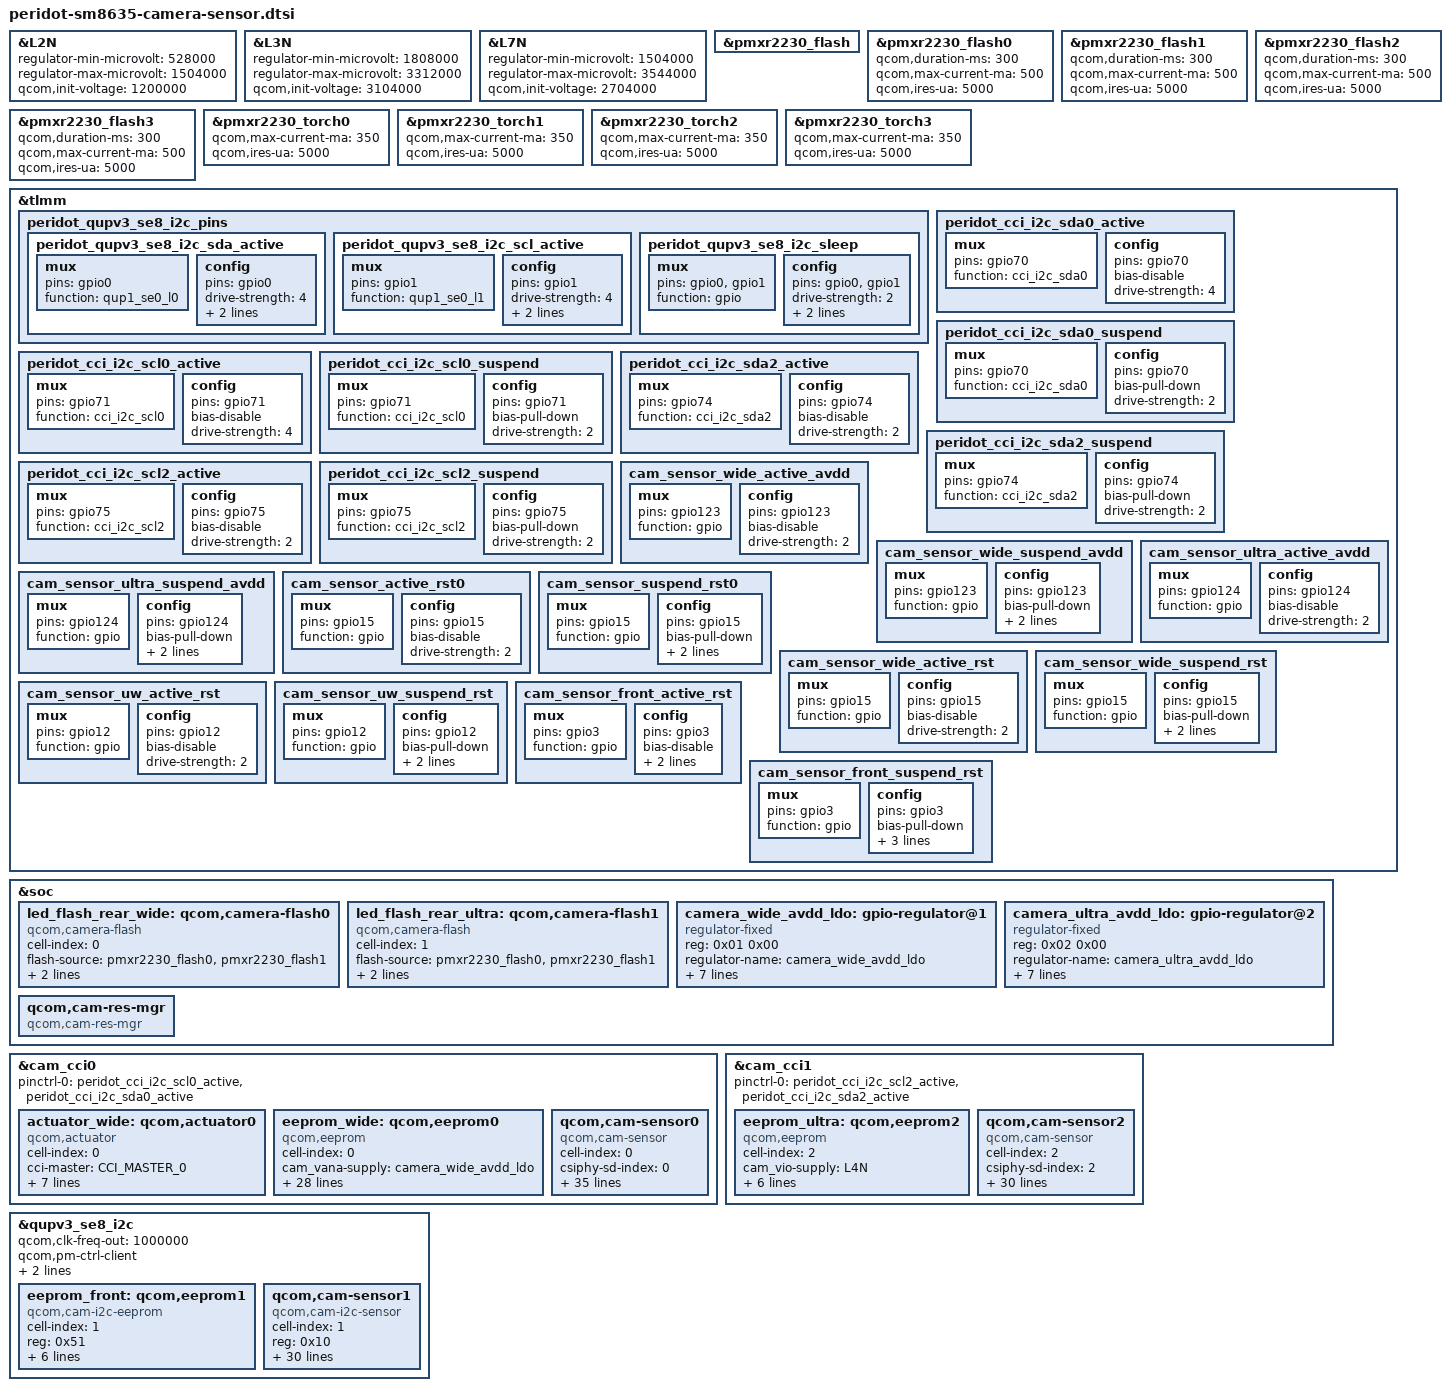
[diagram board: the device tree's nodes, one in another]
#include <dt-bindings/msm-camera.h>

&L2N {
	regulator-min-microvolt = <528000>;
	regulator-max-microvolt = <1504000>;
	qcom,init-voltage = <1200000>;
};

&L3N {
	regulator-min-microvolt = <1808000>;
	regulator-max-microvolt = <3312000>;
	qcom,init-voltage = <3104000>;
};

&L7N {
	regulator-min-microvolt = <1504000>;
	regulator-max-microvolt = <3544000>;
	qcom,init-voltage = <2704000>;
};

&pmxr2230_flash {
	status = "ok";
};

&pmxr2230_flash0 {
	qcom,duration-ms = <300>;
	qcom,max-current-ma = <500>;
	qcom,ires-ua = <5000>;
};

&pmxr2230_flash1 {
	qcom,duration-ms = <300>;
	qcom,max-current-ma = <500>;
	qcom,ires-ua = <5000>;
};

&pmxr2230_flash2 {
	qcom,duration-ms = <300>;
	qcom,max-current-ma = <500>;
	qcom,ires-ua = <5000>;
};

&pmxr2230_flash3 {
	qcom,duration-ms = <300>;
	qcom,max-current-ma = <500>;
	qcom,ires-ua = <5000>;
};

&pmxr2230_torch0{
	qcom,max-current-ma = <350>;
	qcom,ires-ua = <5000>;
};

&pmxr2230_torch1{
	qcom,max-current-ma = <350>;
	qcom,ires-ua = <5000>;
};

&pmxr2230_torch2{
	qcom,max-current-ma = <350>;
	qcom,ires-ua = <5000>;
};

&pmxr2230_torch3{
	qcom,max-current-ma = <350>;
	qcom,ires-ua = <5000>;
};

&tlmm {
	peridot_qupv3_se8_i2c_pins: peridot_qupv3_se8_i2c_pins {
		peridot_qupv3_se8_i2c_sda_active: peridot_qupv3_se8_i2c_sda_active {
			mux {
				pins = "gpio0";
				function = "qup1_se0_l0";
			};

			config {
				pins = "gpio0";
				drive-strength = <4>;
				bias-disable; /* NO PULL */
				qcom,apps;
			};
		};

		peridot_qupv3_se8_i2c_scl_active: peridot_qupv3_se8_i2c_scl_active {
			mux {
				pins = "gpio1";
				function = "qup1_se0_l1";
			};

			config {
				pins = "gpio1";
				drive-strength = <4>;
				bias-disable; /* NO PULL */
				qcom,apps;
			};
		};

		peridot_qupv3_se8_i2c_sleep: peridot_qupv3_se8_i2c_sleep {
			mux {
				pins = "gpio0", "gpio1";
				function = "gpio";
			};

			config {
				pins = "gpio0", "gpio1";
				drive-strength = <2>;
				bias-disable;
				qcom,remote;
			};
		};
	};

	peridot_cci_i2c_sda0_active: peridot_cci_i2c_sda0_active {
		mux {
			/* CLK, DATA */
			pins = "gpio70";
			function = "cci_i2c_sda0";
		};

		config {
			pins = "gpio70";
			bias-disable; /* NO PULL */
			drive-strength = <4>; /* 4 MA */
		};
	};

	peridot_cci_i2c_sda0_suspend: peridot_cci_i2c_sda0_suspend {
		mux {
			/* CLK, DATA */
			pins = "gpio70";
			function = "cci_i2c_sda0";
		};

		config {
			pins = "gpio70";
			bias-pull-down; /* PULL DOWN */
			drive-strength = <2>; /* 2 MA */
		};
	};

	peridot_cci_i2c_scl0_active: peridot_cci_i2c_scl0_active {
		mux {
			/* CLK, DATA */
			pins = "gpio71";
			function = "cci_i2c_scl0";
		};

		config {
			pins = "gpio71";
			bias-disable; /* NO PULL */
			drive-strength = <4>; /* 4 MA */
		};
	};

	peridot_cci_i2c_scl0_suspend: peridot_cci_i2c_scl0_suspend {
		mux {
			/* CLK, DATA */
			pins = "gpio71";
			function = "cci_i2c_scl0";
		};

		config {
			pins = "gpio71";
			bias-pull-down; /* PULL DOWN */
			drive-strength = <2>; /* 2 MA */
		};
	};

	peridot_cci_i2c_sda2_active: peridot_cci_i2c_sda2_active {
		mux {
			/* CLK, DATA */
			pins = "gpio74";
			function = "cci_i2c_sda2";
		};

		config {
			pins = "gpio74";
			bias-disable; /* NO PULL */
			drive-strength = <2>; /* 2 MA */
		};
	};

	peridot_cci_i2c_sda2_suspend: peridot_cci_i2c_sda2_suspend {
		mux {
			/* CLK, DATA */
			pins = "gpio74";
			function = "cci_i2c_sda2";
		};

		config {
			pins = "gpio74";
			bias-pull-down; /* PULL DOWN */
			drive-strength = <2>; /* 2 MA */
		};
	};

	peridot_cci_i2c_scl2_active: peridot_cci_i2c_scl2_active {
		mux {
			/* CLK, DATA */
			pins = "gpio75";
			function = "cci_i2c_scl2";
		};

		config {
			pins = "gpio75";
			bias-disable; /* NO PULL */
			drive-strength = <2>; /* 2 MA */
		};
	};

	peridot_cci_i2c_scl2_suspend: peridot_cci_i2c_scl2_suspend {
		mux {
			/* CLK, DATA */
			pins = "gpio75";
			function = "cci_i2c_scl2";
		};

		config {
			pins = "gpio75";
			bias-pull-down; /* PULL DOWN */
			drive-strength = <2>; /* 2 MA */
		};
	};


	cam_sensor_wide_active_avdd: cam_sensor_wide_active_avdd {
		mux {
			pins = "gpio123";
			function = "gpio";
		};
		config {
			pins = "gpio123";
			bias-disable; /* No PULL */
			drive-strength = <2>; /* 2 MA */
		};
	};
	cam_sensor_wide_suspend_avdd: cam_sensor_wide_suspend_avdd {
		mux {
			pins = "gpio123";
			function = "gpio";
		};
		config {
			pins = "gpio123";
			bias-pull-down; /* PULL DOWN */
			drive-strength = <2>; /* 2 MA */
			output-low;
		};
	};

	cam_sensor_ultra_active_avdd: cam_sensor_ultra_active_avdd {
		mux {
			pins = "gpio124";
			function = "gpio";
		};
		config {
			pins = "gpio124";
			bias-disable; /* No PULL */
			drive-strength = <2>; /* 2 MA */
		};
	};
	cam_sensor_ultra_suspend_avdd: cam_sensor_ultra_suspend_avdd {
		mux {
			pins = "gpio124";
			function = "gpio";
		};
		config {
			pins = "gpio124";
			bias-pull-down; /* PULL DOWN */
			drive-strength = <2>; /* 2 MA */
			output-low;
		};
	};


	cam_sensor_active_rst0: cam_sensor_active_rst0 {
		mux {
			pins = "gpio15";
			function = "gpio";
		};

		config {
			pins = "gpio15";
			bias-disable; /* No PULL */
			drive-strength = <2>; /* 2 MA */
		};
	};

	cam_sensor_suspend_rst0: cam_sensor_suspend_rst0 {
		mux {
			pins = "gpio15";
			function = "gpio";
		};

		config {
			pins = "gpio15";
			bias-pull-down; /* PULL DOWN */
			drive-strength = <2>; /* 2 MA */
			output-low;
		};
	};

	cam_sensor_wide_active_rst: cam_sensor_wide_active_rst {
		mux {
			pins = "gpio15";
			function = "gpio";
		};

		config {
			pins = "gpio15";
			bias-disable; /* No PULL */
			drive-strength = <2>; /* 2 MA */
		};
	};

	cam_sensor_wide_suspend_rst: cam_sensor_wide_suspend_rst {
		mux {
			pins = "gpio15";
			function = "gpio";
		};

		config {
			pins = "gpio15";
			bias-pull-down; /* PULL DOWN */
			drive-strength = <2>; /* 2 MA */
			output-low;
		};
	};

	cam_sensor_uw_active_rst: cam_sensor_uw_active_rst {
		mux {
			pins = "gpio12";
			function = "gpio";
		};

		config {
			pins = "gpio12";
			bias-disable; /* No PULL */
			drive-strength = <2>; /* 2 MA */
		};
	};

	cam_sensor_uw_suspend_rst: cam_sensor_uw_suspend_rst {
		mux {
			pins = "gpio12";
			function = "gpio";
		};

		config {
			pins = "gpio12";
			bias-pull-down; /* PULL DOWN */
			drive-strength = <2>; /* 2 MA */
			output-low;
		};
	};

	cam_sensor_front_active_rst: cam_sensor_front_active_rst {
		mux {
			pins = "gpio3";
			function = "gpio";
		};

		config {
			pins = "gpio3";
			bias-disable; /* No PULL */
			drive-strength = <2>; /* 2 MA */
			qcom,apps;
		};
	};

	cam_sensor_front_suspend_rst: cam_sensor_front_suspend_rst {
		mux {
			pins = "gpio3";
			function = "gpio";
		};

		config {
			pins = "gpio3";
			bias-pull-down; /* PULL DOWN */
			drive-strength = <2>; /* 2 MA */
			output-low;
			qcom,remote;
		};
	};
};

&soc {
	led_flash_rear_wide: qcom,camera-flash0 {
		cell-index = <0>;
		compatible = "qcom,camera-flash";
		flash-source = <&pmxr2230_flash0 &pmxr2230_flash1>;
		torch-source = <&pmxr2230_torch0 &pmxr2230_torch1>;
		switch-source = <&pmxr2230_switch2>;
		status = "ok";
	};

	led_flash_rear_ultra: qcom,camera-flash1 {
		cell-index = <1>;
		compatible = "qcom,camera-flash";
		flash-source = <&pmxr2230_flash0 &pmxr2230_flash1>;
		torch-source = <&pmxr2230_torch0 &pmxr2230_torch1>;
		switch-source = <&pmxr2230_switch2>;
		status = "ok";
	};

	camera_wide_avdd_ldo: gpio-regulator@1 {
		compatible = "regulator-fixed";
		reg = <0x01 0x00>;
		regulator-name = "camera_wide_avdd_ldo";
		regulator-min-microvolt = <2800000>;
		regulator-max-microvolt = <2800000>;
		regulator-enable-ramp-delay = <100>;
		enable-active-high;
		gpio = <&tlmm 123 0>;
		pinctrl-names = "wide_avdd_active", "wide_avdd_suspend";
		pinctrl-0 = <&cam_sensor_wide_active_avdd
					 &cam_sensor_wide_suspend_avdd>;
	};

	camera_ultra_avdd_ldo: gpio-regulator@2 {
		compatible = "regulator-fixed";
		reg = <0x02 0x00>;
		regulator-name = "camera_ultra_avdd_ldo";
		regulator-min-microvolt = <1200000>;
		regulator-max-microvolt = <1200000>;
		regulator-enable-ramp-delay = <100>;
		enable-active-high;
		gpio = <&tlmm 124 0>;
		pinctrl-names = "tele_avdd_active", "tele_avdd_suspend";
		pinctrl-0 = <&cam_sensor_ultra_active_avdd
					&cam_sensor_ultra_suspend_avdd>;
	};

	qcom,cam-res-mgr {
		compatible = "qcom,cam-res-mgr";
		status = "ok";
	};
};

&cam_cci0 {
	pinctrl-0 = <&peridot_cci_i2c_scl0_active &peridot_cci_i2c_sda0_active>;

	actuator_wide: qcom,actuator0 {
		cell-index = <0>;
		compatible = "qcom,actuator";
		cci-master = <CCI_MASTER_0>;
		cam_vaf-supply = <&L3N>;
		cam_vio-supply = <&L4N>;
		regulator-names = "cam_vaf", "cam_vio";
		rgltr-cntrl-support;
		rgltr-min-voltage = <1808000 1800000>;
		rgltr-max-voltage = <3104000 1800000>;
		rgltr-load-current = <150000 106000>;
		status = "ok";
	};

	eeprom_wide: qcom,eeprom0 {
		cell-index = <0>;
		compatible = "qcom,eeprom";
		cam_vana-supply = <&camera_wide_avdd_ldo>;
		cam_vio-supply = <&L4N>;
		cam_vdig-supply = <&L1N>;
		cam_vaf-supply = <&L3N>;
		cam_clk-supply = <&cam_cc_titan_top_gdsc>;
		regulator-names = "cam_vana", "cam_vio",
			"cam_vdig", "cam_vaf", "cam_clk";
		rgltr-cntrl-support;
		rgltr-min-voltage = <2800000 1800000 1104000 1808000 0>;
		rgltr-max-voltage = <2800000 1800000 1104000 3312000 0>;
		rgltr-load-current = <102000 106000 796500 150000 0>;
		gpio-no-mux = <0>;
		pinctrl-names = "cam_default", "cam_suspend";
		pinctrl-0 = <&cam_sensor_mclk0_active
			&cam_sensor_wide_active_rst>;
		pinctrl-1 = <&cam_sensor_mclk0_suspend
			&cam_sensor_wide_suspend_rst>;
		gpios = <&tlmm 64 0>, <&tlmm 15 0>;
		gpio-reset = <1>;
		gpio-req-tbl-num = <0 1>;
		gpio-req-tbl-flags = <1 0>;
		gpio-req-tbl-label = "CAMIF_MCLK0", "CAM_RESET_WIDE";
		cci-master = <CCI_MASTER_0>;
		clocks = <&camcc CAM_CC_MCLK0_CLK>;
		clock-names = "cam_clk";
		clock-cntl-level = "nominal";
		clock-rates = <19200000>;
		status = "ok";
	};


	qcom,cam-sensor0 {
		cell-index = <0>;
		compatible = "qcom,cam-sensor";
		csiphy-sd-index = <0>;
		actuator-src = <&actuator_wide>;
		led-flash-src = <&led_flash_rear_wide>;
		eeprom-src = <&eeprom_wide>;
		sensor-position-roll = <90>;
		sensor-position-pitch = <0>;
		sensor-position-yaw = <180>;
		cam_vana-supply = <&camera_wide_avdd_ldo>;
		cam_vio-supply = <&L4N>;
		cam_vdig-supply = <&L1N>;
		cam_vaf-supply = <&L3N>;
		cam_clk-supply = <&cam_cc_titan_top_gdsc>;
		regulator-names = "cam_vana", "cam_vio",
			"cam_vdig", "cam_vaf", "cam_clk";
		rgltr-cntrl-support;
		rgltr-min-voltage = <2800000 1800000 1104000 1808000 0>;
		rgltr-max-voltage = <2800000 1800000 1104000 3312000 0>;
		rgltr-load-current = <102000 106000 796500 150000 0>;
		gpio-no-mux = <0>;
		pinctrl-names = "cam_default", "cam_suspend";
		pinctrl-0 = <&cam_sensor_mclk0_active
			&cam_sensor_wide_active_rst>;
		pinctrl-1 = <&cam_sensor_mclk0_suspend
			&cam_sensor_wide_suspend_rst>;
		gpios = <&tlmm 64 0>, <&tlmm 15 0>;
		gpio-reset = <1>;
		gpio-req-tbl-num = <0 1>;
		gpio-req-tbl-flags = <1 0>;
		gpio-req-tbl-label = "CAMIF_MCLK0", "CAM_RESET_WIDE";
		cci-master = <CCI_MASTER_0>;
		clocks = <&camcc CAM_CC_MCLK0_CLK>;
		clock-names = "cam_clk";
		clock-cntl-level = "nominal";
		clock-rates = <19200000>;
		status = "ok";
	};
};

&cam_cci1 {
	pinctrl-0 = <&peridot_cci_i2c_scl2_active &peridot_cci_i2c_sda2_active>;

	eeprom_ultra: qcom,eeprom2 {
		cell-index = <2>;
		compatible = "qcom,eeprom";
		cam_vio-supply = <&L4N>;
		regulator-names = "cam_vio";
		rgltr-cntrl-support;
		rgltr-min-voltage = <1800000>;
		rgltr-max-voltage = <1800000>;
		rgltr-load-current = <300>;
		cci-master = <CCI_MASTER_0>;
		status = "ok";
	};


	qcom,cam-sensor2 {
		cell-index = <2>;
		compatible = "qcom,cam-sensor";
		csiphy-sd-index = <2>;
		led-flash-src = <&led_flash_rear_ultra>;
		sensor-position-roll = <90>;
		sensor-position-pitch = <0>;
		sensor-position-yaw = <180>;
		eeprom-src = <&eeprom_ultra>;
		cam_vana-supply = <&L7N>;
		cam_vio-supply = <&L4N>;
		cam_vdig-supply = <&camera_ultra_avdd_ldo>;
		cam_clk-supply = <&cam_cc_titan_top_gdsc>;
		regulator-names = "cam_vana", "cam_vio", "cam_vdig", "cam_clk";
		rgltr-cntrl-support;
		rgltr-min-voltage = <1504000 1800000 1200000 0>;
		rgltr-max-voltage = <3544000 1800000 1200000 0>;
		rgltr-load-current = <57900 300 216200 0>;
		gpio-no-mux = <0>;
		pinctrl-names = "cam_default", "cam_suspend";
		pinctrl-0 = <&cam_sensor_mclk2_active
			&cam_sensor_uw_active_rst>;
		pinctrl-1 = <&cam_sensor_mclk2_suspend
			&cam_sensor_uw_suspend_rst>;
		gpios = <&tlmm 66 0>, <&tlmm 12 0>;
		gpio-reset = <1>;
		gpio-req-tbl-num = <0 1>;
		gpio-req-tbl-flags = <1 0>;
		gpio-req-tbl-label = "CAMIF_MCLK2", "CAM_RESET_ULTRA";
		cci-master = <CCI_MASTER_0>;
		clocks = <&camcc CAM_CC_MCLK2_CLK>;
		clock-names = "cam_clk";
		clock-cntl-level = "nominal";
		clock-rates = <19200000>;
		status = "ok";
	};
};

&qupv3_se8_i2c {
	status = "ok";
	qcom,clk-freq-out = <1000000>;
	qcom,pm-ctrl-client;

	pinctrl-0 = <&peridot_qupv3_se8_i2c_sda_active>, <&peridot_qupv3_se8_i2c_scl_active>;

	eeprom_front: qcom,eeprom1 {
		cell-index = <1>;
		reg = <0x51>;
		compatible = "qcom,cam-i2c-eeprom";
		cam_vio-supply = <&L5N>;
		regulator-names = "cam_vio";
		rgltr-cntrl-support;
		rgltr-min-voltage = <1800000>;
		rgltr-max-voltage = <1800000>;
		rgltr-load-current = <300>;
		status = "ok";
	};

	qcom,cam-sensor1 {
		cell-index = <1>;
		reg = <0x10>;
		compatible = "qcom,cam-i2c-sensor";
		csiphy-sd-index = <4>;
		sensor-position-roll = <270>;
		sensor-position-pitch = <0>;
		sensor-position-yaw = <0>;
		aon-camera-id = <AON_CAM1>;
		eeprom-src = <&eeprom_front>;
		cam_vana-supply = <&L6N>;
		cam_vio-supply = <&L5N>;
		cam_vdig-supply = <&L2N>;
		cam_clk-supply = <&cam_cc_titan_top_gdsc>;
		regulator-names = "cam_vana", "cam_vio",
			"cam_vdig", "cam_clk";
		rgltr-cntrl-support;
		rgltr-min-voltage = <2800000 1800000 528000 0>;
		rgltr-max-voltage = <2800000 1800000 1504000 0>;
		rgltr-load-current = <43500 300 93000 0>;
		gpio-no-mux = <0>;
		pinctrl-names = "cam_default", "cam_suspend";
		pinctrl-0 = <&cam_sensor_mclk4_active
			&cam_sensor_front_active_rst>;
		pinctrl-1 = <&cam_sensor_mclk4_suspend
			&cam_sensor_front_suspend_rst>;
		gpios = <&tlmm 68 0>, <&tlmm 3 0>;
		gpio-reset = <1>;
		gpio-req-tbl-num = <0 1>;
		gpio-req-tbl-flags = <1 0>;
		gpio-req-tbl-label = "CAMIF_MCLK4", "CAM_RESET_FRONT";
		clocks = <&camcc CAM_CC_MCLK4_CLK>;
		clock-names = "cam_clk";
		clock-cntl-level = "nominal";
		clock-rates = <19200000>;
		status = "ok";
	};
};
